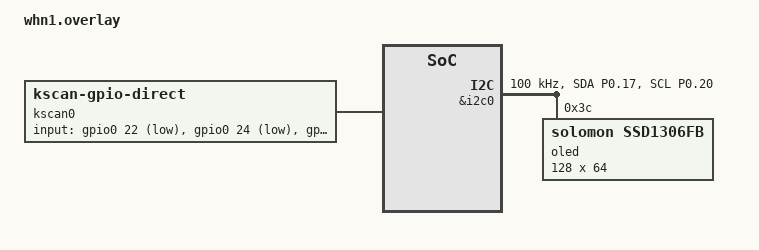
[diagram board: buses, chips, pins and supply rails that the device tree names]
#include <dt-bindings/gpio/gpio.h>
#include <dt-bindings/zmk/keys.h>

/ {
    chosen {
        zmk,kscan = &kscan0;
        zmk,display = &oled;
    };

    /* 直接GPIO按键扫描（非矩阵） */
    kscan0: kscan {
        compatible = "zmk,kscan-gpio-direct";
        wakeup-source;
        debounce-press-ms = <5>;
        debounce-release-ms = <5>;

        /* 16个按键引脚（根据您提供的列表）：
         * 1: 0.22 (F7)
         * 2: 0.24 (F3)
         * 3: 1.00 (F1)
         * 4: 0.11 (D)
         * 5: 1.04 (S)
         * 6: 1.06 (W)
         * 7: 1.01 (A)
         * 8: 1.02 (功能键1)
         * 9: 1.07 (功能键2)
         * 10: 0.09 (I)
         * 11: 0.10 (O)
         * 12: 1.11 (P)
         * 13: 1.13 (H)
         * 14: 1.15 (J)
         * 15: 0.02 (K)
         * 16: 0.29 (L)
         */
        input-gpios
            = <&gpio0 22 (GPIO_ACTIVE_LOW | GPIO_PULL_UP)>
            , <&gpio0 24 (GPIO_ACTIVE_LOW | GPIO_PULL_UP)>
            , <&gpio1  0 (GPIO_ACTIVE_LOW | GPIO_PULL_UP)>
            , <&gpio0 11 (GPIO_ACTIVE_LOW | GPIO_PULL_UP)>
            , <&gpio1  4 (GPIO_ACTIVE_LOW | GPIO_PULL_UP)>
            , <&gpio1  6 (GPIO_ACTIVE_LOW | GPIO_PULL_UP)>
            , <&gpio1  1 (GPIO_ACTIVE_LOW | GPIO_PULL_UP)>
            , <&gpio1  2 (GPIO_ACTIVE_LOW | GPIO_PULL_UP)>
            , <&gpio1  7 (GPIO_ACTIVE_LOW | GPIO_PULL_UP)>
            , <&gpio0  9 (GPIO_ACTIVE_LOW | GPIO_PULL_UP)>
            , <&gpio0 10 (GPIO_ACTIVE_LOW | GPIO_PULL_UP)>
            , <&gpio1 11 (GPIO_ACTIVE_LOW | GPIO_PULL_UP)>
            , <&gpio1 13 (GPIO_ACTIVE_LOW | GPIO_PULL_UP)>
            , <&gpio1 15 (GPIO_ACTIVE_LOW | GPIO_PULL_UP)>
            , <&gpio0  2 (GPIO_ACTIVE_LOW | GPIO_PULL_UP)>
            , <&gpio0 29 (GPIO_ACTIVE_LOW | GPIO_PULL_UP)>;
    };

    /* I2C引脚配置：SDA=0.17, SCL=0.20 */
    &pinctrl {
        i2c0_default: i2c0_default {
            group1 {
                psels = <NRF_PSEL(TWIM_SDA, 0, 17)>,
                        <NRF_PSEL(TWIM_SCL, 0, 20)>;
            };
        };
    };

    &i2c0 {
        status = "okay";
        pinctrl-0 = <&i2c0_default>;
        pinctrl-names = "default";
        clock-frequency = <I2C_BITRATE_STANDARD>;

        oled: ssd1306@3c {
            compatible = "solomon,ssd1306fb";
            reg = <0x3c>;
            width = <128>;
            height = <64>;
            segment-offset = <0>;
            page-offset = <0>;
            display-offset = <0>;
            multiplex-ratio = <63>;
            segment-remap;
            com-invdir;
            com-sequential;
            prechargep = <0x22>;
        };
    };
};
